# RA4M1 register map
Vendor: Renesas Electronics Corporation; Series: RA4; File version: 1.2
CPU: CM4 r0p1, little endian, MPU, FPU, VTOR, 4 interrupt priority bits
Registers are 8-bit, read-write, reset 0x0 unless marked. A register's access mark holds for its fields unless they carry their own. Offsets are from the block's base; [hi:lo] are bit positions; 'fields as' and 'values as' point back to an identical list.

## SPMON — CPU Stack Pointer Monitor
Base 0x40000D00
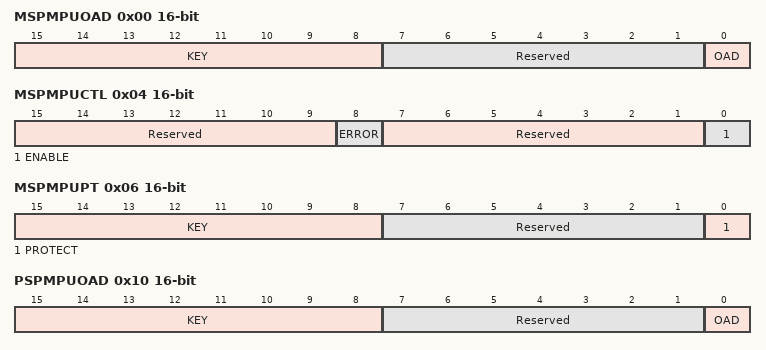
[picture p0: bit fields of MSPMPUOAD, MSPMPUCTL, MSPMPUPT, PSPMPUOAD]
0x00 MSPMPUOAD 16-bit — Stack Pointer Monitor Operation After Detection Register
  [15:8] KEY wo — Write Keyword The data written to these bits are not stored.
    165=Writing to the OAD bit is valid, when the KEY bits are written 0xA5; other=others (Writing to the OAD bit is invalid.)
  [7:1] Reserved — These bits are read as 0000000. The write value should be 0000000.
  [0] OAD — Operation after detection
    0=Non-maskable interrupt; 1=Reset
0x04 MSPMPUCTL 16-bit (reset mask 0xFEFF) — Stack Pointer Monitor Access Control Register
  [15:9] Reserved — These bits are read as 0000000. The write value should be 0000000.
  [8] ERROR — Stack Pointer Monitor Error Flag
    0=Stack pointer has not overflowed or underflowed; 1=Stack pointer has overflowed or underflowed
  [7:1] Reserved — These bits are read as 0000000. The write value should be 0000000.
  [0] ENABLE — Stack Pointer Monitor Enable
    0=Stack pointer monitor is disabled; 1=Stack pointer monitor is enabled
0x06 MSPMPUPT 16-bit — Stack Pointer Monitor Protection Register
  [15:8] KEY wo — Write Keyword The data written to these bits are not stored.
    165=Writing to the PROTECT bit is valid, when the KEY bits are written 0xA5; other=others (Writing to the PROTECT bit is invalid.)
  [7:1] Reserved — These bits are read as 0000000. The write value should be 0000000.
  [0] PROTECT — Protection of register (MSPMPUAC, MSPMPUSA and MSPMPUSE)
    0=Stack Pointer Monitor register writing is possible; 1=Stack Pointer Monitor register writing is protected
0x08 MSPMPUSA 32-bit (reset mask 0x3) — Main Stack Pointer (MSP) Monitor Start Address Register
  [31:0] MSPMPUSA range 0x1FF00000..0x200FFFFC — Region start address register Address where the region starts, for use in region determination. NOTE: Range: 0x1FF00000-0x200FFFFC The low-order 2 bits are fixed to 0.
0x0C MSPMPUEA 32-bit reset 0x3 (reset mask 0x3) — Main Stack Pointer (MSP) Monitor End Address Register
  [31:0] MSPMPUEA range 0x1FF00003..0x200FFFFF — Region end address register Address where the region starts, for use in region determination. NOTE: Range: 0x1FF00003-0x200FFFFF The low-order 2 bits are fixed to 1.
0x10 PSPMPUOAD 16-bit — Stack Pointer Monitor Operation After Detection Register
  [15:8] KEY wo — Key Code The data written to these bits are not stored.
    values as MSPMPUOAD.KEY
  [7:1] Reserved — These bits are read as 0000000. The write value should be 0000000.
  [0] OAD — Operation after detection
    0=Non-maskable interrupt; 1=Reset
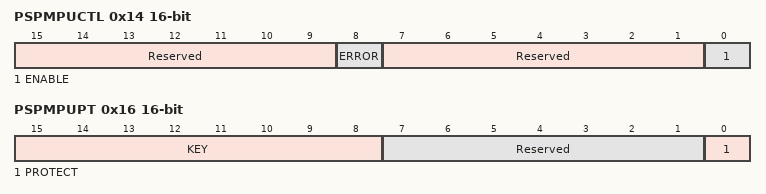
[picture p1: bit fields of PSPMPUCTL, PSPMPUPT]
0x14 PSPMPUCTL 16-bit (reset mask 0xFEFF) — Stack Pointer Monitor Access Control Register
  fields as MSPMPUCTL
0x16 PSPMPUPT 16-bit — Stack Pointer Monitor Protection Register
  [15:8] KEY wo — Key Code The data written to these bits are not stored.
    values as MSPMPUPT.KEY
  [7:1] Reserved — These bits are read as 0000000. The write value should be 0000000.
  [0] PROTECT — Protection register (PSPMPUAC, PSPMPUSA and PSPMPUSE)
    values as MSPMPUPT.PROTECT
0x18 PSPMPUSA 32-bit (reset mask 0x3) — Process Stack Pointer (PSP) Monitor Start Address Register
  [31:0] PSPMPUSA range 0x1FF00000..0x200FFFFC — Region start address register Address where the region starts, for use in region determination. NOTE: Range: 0x1FF00000-0x200FFFFC The low-order 2 bits are fixed to 0.
0x1C PSPMPUEA 32-bit reset 0x3 (reset mask 0x3) — Process Stack Pointer (PSP) Monitor End Address Register
  [31:0] PSPMPUEA range 0x1FF00003..0x200FFFFF — Region end address register Address where the region starts, for use in region determination. NOTE: Range: 0x1FF00003-0x200FFFFF The low-order 2 bits are fixed to 1.
